# CY8C4xxx register map
File version: 0.1
Registers are 8-bit, read-write, no defined reset value unless marked. A register's access mark holds for its fields unless they carry their own. Offsets are from the block's base; [hi:lo] are bit positions; {n}, {i} and the like mark numbered series; 'fields as' and 'values as' point back to an identical list.

## UDB_P0_U0 — Single UDB Configuration
Base 0x400F3000; alternate view of UDB
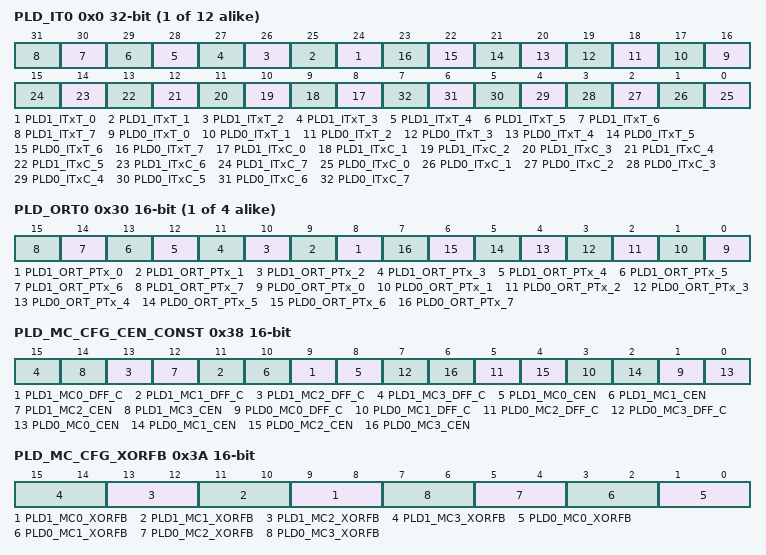
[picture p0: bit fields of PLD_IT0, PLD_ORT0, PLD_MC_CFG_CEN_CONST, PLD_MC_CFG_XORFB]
{0x0+4i} PLD_IT{i} 32-bit (i=0..11) — PLD Input Terms
  [n+24] PLD1_ITxT_{n} (n=0..7) — True input term. Bit position corresponds to product term.
  [n+16] PLD0_ITxT_{n} (n=0..7) — True input term. Bit position corresponds to product term.
  [n+8] PLD1_ITxC_{n} (n=0..7) — Complement input term. Bit position corresponds to product term
  [n] PLD0_ITxC_{n} (n=0..7) — Complement input term. Bit position corresponds to product term
{0x30+2i} PLD_ORT{i} 16-bit (i=0..3) — PLD OR Terms
  [n+8] PLD1_ORT_PTx_{n} (n=0..7) — OR term. Bit position corresponds to product term.
  [n] PLD0_ORT_PTx_{n} (n=0..7) — OR term. Bit position corresponds to product term.
0x38 PLD_MC_CFG_CEN_CONST 16-bit — Macrocell configuration for Carry Enable and Constant
  [2n+9] PLD1_MC{n}_DFF_C (n=0..3) — DFF Constant
    0=NOINV; 1=INVERTED
  [2n+8] PLD1_MC{n}_CEN (n=0..3) — Carry enable
    0=DISABLE; 1=ENABLE
  [2n+1] PLD0_MC{n}_DFF_C (n=0..3) — DFF Constant
    0=NOINV; 1=INVERTED
  [2n] PLD0_MC{n}_CEN (n=0..3) — Carry enable
    0=DISABLE; 1=ENABLE
0x3A PLD_MC_CFG_XORFB 16-bit — PLD Macro cell XOR feedback
  [all] fields
    0=DFF; 1=CARRY; 2=TFF_H; 3=TFF_L
  [2n+9:2n+8] PLD1_MC{n}_XORFB (n=0..3) — XOR feedback
  [2n+1:2n] PLD0_MC{n}_XORFB (n=0..3) — XOR feedback
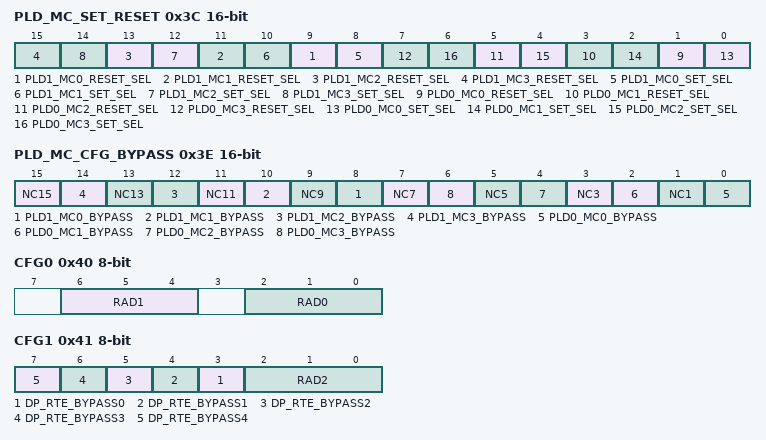
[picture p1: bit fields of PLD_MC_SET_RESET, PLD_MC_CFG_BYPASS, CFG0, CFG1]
0x3C PLD_MC_SET_RESET 16-bit — PLD Macro cell Set Reset Selection
  [all] fields
    0=DISABLE; 1=ENABLE
  [2n+9] PLD1_MC{n}_RESET_SEL (n=0..3) — Reset select enable
  [2n+8] PLD1_MC{n}_SET_SEL (n=0..3) — Set select enable
  [2n+1] PLD0_MC{n}_RESET_SEL (n=0..3) — Reset select enable
  [2n] PLD0_MC{n}_SET_SEL (n=0..3) — Set select enable
0x3E PLD_MC_CFG_BYPASS 16-bit — PLD Macro cell Bypass control
  [15] NC15 — Spare register bit
  [2n+8] PLD1_MC{n}_BYPASS (n=0..3) — Bypass selection
    0=REGISTER; 1=COMBINATIONAL
  [13] NC13 — Spare register bit
  [11] NC11 — Spare register bit
  [9] NC9 — Spare register bit
  [7] NC7 — Spare register bit
  [2n] PLD0_MC{n}_BYPASS (n=0..3) — Bypass selection
    0=REGISTER; 1=COMBINATIONAL
  [5] NC5 — Spare register bit
  [3] NC3 — Spare register bit
  [1] NC1 — Spare register bit
0x40 CFG0 — Datapath Input Selection - RAD1 RAD0. Address bits 0 and 1 to the dynamic configuration RAM
  [6:4] RAD1 — Datapath Permutable Input Mux
    0=OFF; {v}=DP_IN{v-1} (v=1..6)
  [2:0] RAD0 — Datapath Permutable Input Mux
    0=OFF; {v}=DP_IN{v-1} (v=1..6)
0x41 CFG1 — Datapath Input Selection - RAD2. Address bit 2 to the dynamic configuration RAM
  [n+3] DP_RTE_BYPASS{n} (n=0..4) — DP_In bypass ctl
    0=DP_IN{n}_ROUTE; 1=DP_IN{n}_BYPASS
  [2:0] RAD2 — Datapath Permutable Input Mux
    0=OFF; {v}=DP_IN{v-1} (v=1..6)
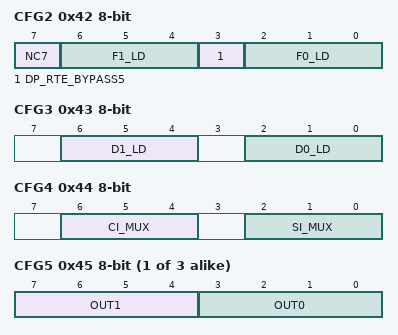
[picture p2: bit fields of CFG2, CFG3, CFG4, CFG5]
0x42 CFG2 — Datapath Input Selection - F1_LD, F0_LD.
  [7] NC7 — Spare register bit
  [6:4] F1_LD — Datapath Permutable Input Mux
    0=OFF; {v}=DP_IN{v-1} (v=1..6)
  [3] DP_RTE_BYPASS5 — DP_In bypass ctl
    0=DP_IN5_ROUTE; 1=DP_IN5_BYPASS
  [2:0] F0_LD — Datapath Permutable Input Mux
    0=OFF; {v}=DP_IN{v-1} (v=1..6)
0x43 CFG3 — Datapath Input Selection - D1_LD, D0_LD.
  [6:4] D1_LD — Datapath Permutable Input Mux
    0=OFF; {v}=DP_IN{v-1} (v=1..6)
  [2:0] D0_LD — Datapath Permutable Input Mux
    0=OFF; {v}=DP_IN{v-1} (v=1..6)
0x44 CFG4 — Datapath Input Selection - CI_MUX SI_MUX.
  [6:4] CI_MUX — Datapath Permutable Input Mux
    0=OFF; {v}=DP_IN{v-1} (v=1..6)
  [2:0] SI_MUX — Datapath Permutable Input Mux
    0=OFF; {v}=DP_IN{v-1} (v=1..6)
{0x40+i} CFG{i} (i=5..7) — Datapath Output Selection for OUT{2i-9} OUT{2i-10}
  [7:4] OUT{2i-9} — Datapath Permutable Output Mux
    0=CE0; 1=CL0; 2=Z0; 3=FF0; 4=CE1; 5=CL1; 6=Z1; 7=FF1; 8=OV_MSB; 9=CO_MSB; 10=CMSBO; 11=SO; 12=F0_BLK_STAT; 13=F1_BLK_STAT; 14=F0_BUS_STAT; 15=F1_BUS_STAT
  [3:0] OUT{2i-10} — Datapath Permutable Output Mux
    values as OUT{2i-9}
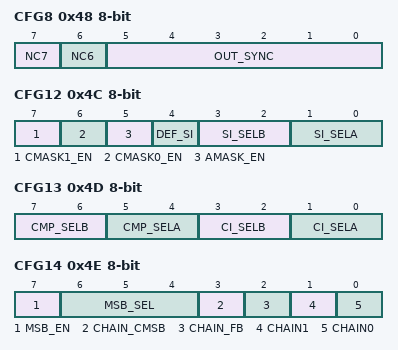
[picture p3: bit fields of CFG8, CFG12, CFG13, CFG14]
0x48 CFG8 — Datapath Output Synchronization Option
  [7] NC7 — Spare register bit
  [6] NC6 — Spare register bit
  [5:0] OUT_SYNC — Datapath Output Synchronization. Each datapath output can be registered (default,0), or combinational (1)
    0=REGISTERED; 1=COMBINATIONAL
0x49 CFG9 — Datapath ALU Mask
  [7:0] AMASK — Datapath ALU Mask. The mask value in this register is applied to the output of the Datapath ALU result before the result is stored. The AMASK_EN bit (CFG12) must be set for the mask to be operational.
0x4A CFG10 — Datapath Compare 0 Mask
  [7:0] CMASK0 — Datapath Compare 0 Mask. The mask value in this register is applied to the output of the Accumulator 0 before it is used for comparison in Compare block 0. The CMASK0_EN bit (CFG12) must be set for the mask to be operational.
0x4B CFG11 — Datapath Compare 1 Mask
  [7:0] CMASK0 — Datapath Compare 1 Mask. The mask value in this register is applied to the selected Compare 1 block input (Accumulator 0 or Accumulator 1) before it is used for comparison. The CMASK1_EN bit (CFG12) must be set for the mask to be operational.
0x4C CFG12 — Datapath mask enables and shift in configuration
  [7] CMASK1_EN — Datapath mask enable
    0=DISABLE; 1=ENABLE
  [6] CMASK0_EN — Datapath mask enable
    0=DISABLE; 1=ENABLE
  [5] AMASK_EN — Datapath mask enable
    0=DISABLE; 1=ENABLE
  [4] DEF_SI — Datapath default shift value
    0=DEFAULT_0; 1=DEFAULT_1
  [3:2] SI_SELB — Datapath shift in source select
    0=DEFAULT; 1=REGISTERED; 2=ROUTE; 3=CHAIN
  [1:0] SI_SELA — Datapath shift in source select
    0=DEFAULT; 1=REGISTERED; 2=ROUTE; 3=CHAIN
0x4D CFG13 — Datapath carry in and compare configuration
  [7:6] CMP_SELB — Datapath compare select
    0=A1_D1; 1=A1_A0; 2=A0_D1; 3=A0_A0
  [5:4] CMP_SELA — Datapath compare select
    0=A1_D1; 1=A1_A0; 2=A0_D1; 3=A0_A0
  [3:2] CI_SELB — Datapath carry in source select
    0=DEFAULT; 1=REGISTERED; 2=ROUTE; 3=CHAIN
  [1:0] CI_SELA — Datapath carry in source select
    0=DEFAULT; 1=REGISTERED; 2=ROUTE; 3=CHAIN
0x4E CFG14 — Datapath chaining and MSB configuration
  [7] MSB_EN — Datapath MSB selection enable
    0=DISABLE; 1=ENABLE
  [6:4] MSB_SEL — Datapath MSB Selection
    {v}=BIT{v} (v=0..7)
  [3] CHAIN_CMSB — Datapath CRC MSB chaining enable
    0=DISABLE; 1=ENABLE
  [2] CHAIN_FB — Datapath CRC feedback chaining enable
    0=DISABLE; 1=ENABLE
  [1] CHAIN1 — Datapath condition chaining enable
    0=DISABLE; 1=ENABLE
  [0] CHAIN0 — Datapath condition chaining enable
    0=DISABLE; 1=ENABLE
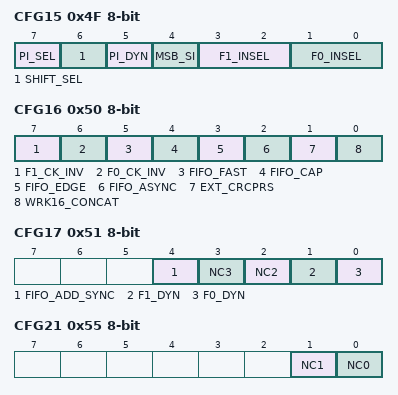
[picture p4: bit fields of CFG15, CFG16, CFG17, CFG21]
0x4F CFG15 — Datapath FIFO, shift and parallel input control
  [7] PI_SEL — Datapath parallel input selection
    0=NORMAL; 1=PARALLEL
  [6] SHIFT_SEL — Datapath shift out selection
    0=SOL_MSB; 1=SOR
  [5] PI_DYN — Enable for dynamic control of parallel data input (PI) mux.
    0=DISABLE; 1=ENABLE
  [4] MSB_SI — Arithmetic shift right operation shift in selection
    0=DEFAULT; 1=MSB
  [3:2] F1_INSEL — Datapath FIFO Configuration
    0=INPUT; 1=OUTPUT_A0; 2=OUTPUT_A1; 3=OUTPUT_ALU
  [1:0] F0_INSEL — Datapath FIFO Configuration
    0=INPUT; 1=OUTPUT_A0; 2=OUTPUT_A1; 3=OUTPUT_ALU
0x50 CFG16 — Datapath FIFO and register access configuration control
  [7] F1_CK_INV — FIFO Clock Invert. When this bit is set, the polarity of the clock for the given FIFO will be inverted, with respect to the polarity of the selected Datapath clock.
    0=NORMAL; 1=INVERT
  [6] F0_CK_INV — FIFO Clock Invert. When this bit is set, the polarity of the clock for the given FIFO will be inverted, with respect to the polarity of the selected Datapath clock.
    0=NORMAL; 1=INVERT
  [5] FIFO_FAST — FIFO Fast Mode. When this bit is set, the FIFO write logic is clocked by the application bus clock. Lowers the latency of capture timing, at the expense of additional power.
    0=DISABLE; 1=ENABLE
  [4] FIFO_CAP — FIFO Software Capture Mode. When this bit is set, a read of A0 or A1 triggers a capture into F0 or F1 respectively. This function follows the chaining configuration. All accumulators in the chain from a given block to the MS block in the chain are capture
    0=DISABLE; 1=ENABLE
  [3] FIFO_EDGE — Edge/level sensitive FIFO write control (Fx_LD). Only applies to FIFO configured in output mode
    0=LEVEL; 1=EDGE
  [2] FIFO_ASYNC — Asynchronous FIFO clocking support
    0=DISABLE; 1=ENABLE
  [1] EXT_CRCPRS — External CRC/PRS mode
    0=INTERNAL; 1=EXTERNAL
  [0] WRK16_CONCAT — Datapath register access mode
    0=DEFAULT; 1=CONCATENATE
0x51 CFG17 — Datapath FIFO control
  [4] FIFO_ADD_SYNC — Adds an additional sync flip-flop to FIFO block status.
    0=DISABLE; 1=ENABLE
  [3] NC3 — Spare register bit
  [2] NC2 — Spare register bit
  [1] F1_DYN
    0=STATIC; 1=DYNAMIC
  [0] F0_DYN — When this bit is set, the associated FIFO configuration may be dynamically controlled.
    0=STATIC; 1=DYNAMIC
0x52 CFG18 — Control Register Mode 0 (used in conjunction with Control Register Mode 1)
  [7:0] CTL_MD0 — CTL_MD1 and CTL_MD0 are concatenated to form an encoding for the mode of each control bit in the control register.
    0=DIRECT; 1=SYNC; 2=DOUBLE_SYNC; 3=PULSE
0x53 CFG19 — Control Register Mode 1 (used in conjunction with Control Register Mode 0)
  [7:0] CTL_MD1 — CTL_MD1 and CTL_MD0 are concatenated to form an encoding for the mode of each control bit in the control register.
    0=DIRECT; 1=SYNC; 2=DOUBLE_SYNC; 3=PULSE
0x54 CFG20 — Status Register input mode selection
  [7:0] STAT_MD — Mode selection for each bit of the status register. A '0' is transparent mode, where internal routing is read idrectly by CPU firmware. A '1' is sticky-clear-on-read mode, where once the given bit is set, it will stay set until the CPU reads the bit.
0x55 CFG21 — Spare register bits
  [1] NC1 — Spare register bit
  [0] NC0 — Spare register bit
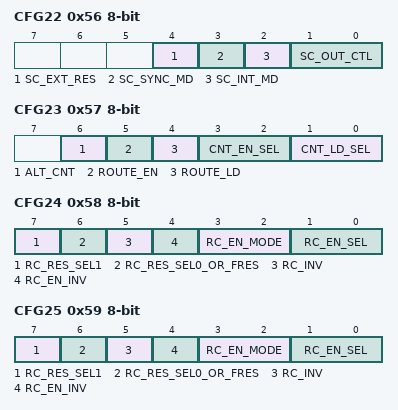
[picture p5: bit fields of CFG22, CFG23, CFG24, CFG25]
0x56 CFG22 — SC block configuration control
  [4] SC_EXT_RES — Control register external reset operation. This bit supports autonomous usage of the control register, where a routed reset should clear the writable input registers. By default this is off because the CPU writable register can be cleared in firmware. In
    0=DISABLED; 1=ENABLED
  [3] SC_SYNC_MD — SC Sync Mode - controls when the status register operates as a 4-bit double synchronizer module
    0=NORMAL; 1=SYNC_MODE
  [2] SC_INT_MD — SC Interrupt Mode - controls when the UDB driving an interrupt generated from the masked OR reduction of status bits 6 to 0
    0=NORMAL; 1=INT_MODE
  [1:0] SC_OUT_CTL — Selects the output source for the Status and Control routing connections
    0=CONTROL; 1=PARALLEL; 2=COUNTER
0x57 CFG23 — Counter Control
  [6] ALT_CNT — Configure the alternate operating mode of the counter
    0=DEFAULT_MODE; 1=ALT_MODE
  [5] ROUTE_EN — Configure the counter enable signal for routing input
    0=DISABLE; 1=ROUTED
  [4] ROUTE_LD — Configure the counter load signal for routing input
    0=DISABLE; 1=ROUTED
  [3:2] CNT_EN_SEL — Selects the routing inputs for the counter enable signal
    0=SC_IN4; 1=SC_IN5; 2=SC_IN6; 3=SC_IO
  [1:0] CNT_LD_SEL — Selects the routing inputs for the counter load signal
    {v}=SC_IN{v} (v=0..3)
0x58 CFG24 — PLD0 Clock and Reset control
  [7] RC_RES_SEL1 — Configures the routed reset for the associated UDB component block. The meaning of this bit depends on the value of ALT RES (CFG31). ?When ALT RES = '0' - This bit is not used. ?When ALT RES = '1' - The bits {RC_SEL1,RC_SEL0_OR_FRES} select the RC routing
  [6] RC_RES_SEL0_OR_FRES — Configures the routed or firmware reset for the associated UDB component block. The meaning of this bit depends on the value of ALT RES (CFG31). ?When ALT RES = '0' - This bit is a firmware reset. ?When ALT RES = '1' - The bits {RC_SEL1,RC_SEL0_OR_FRES} s
  [5] RC_INV — Optionally inverts the clock selection for the associated UDB component block.
    0=NOINV; 1=INVERT
  [4] RC_EN_INV — Optionally inverts the clock enable selection for the associated UDB component blocks.
    0=NOINV; 1=INVERT
  [3:2] RC_EN_MODE — Selects the operating mode for the clock to the associated UDB component block.
    0=OFF; 1=ON; 2=POSEDGE; 3=LEVEL
  [1:0] RC_EN_SEL — Selects channel route for enable control to the associated UDB component block
    {v}=RC_IN{v} (v=0..3)
0x59 CFG25 — PLD1 Clock and Reset control
  fields as CFG24
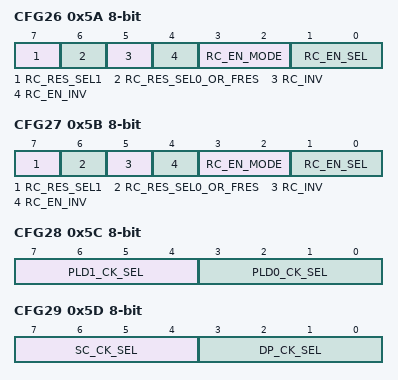
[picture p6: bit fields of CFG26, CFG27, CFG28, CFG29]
0x5A CFG26 — Datapath Clock and Reset control
  fields as CFG24
0x5B CFG27 — Status/Control Clock and Reset control
  fields as CFG24
0x5C CFG28 — Clock Selection for PLD1 and PLD0
  [7:4] PLD1_CK_SEL — Clock selection registers
    {v}=GCLK{v} (v=0..7); 8=EXT_CLK; 9=SYSCLK
  [3:0] PLD0_CK_SEL — Clock selection registers
    {v}=GCLK{v} (v=0..7); 8=EXT_CLK; 9=SYSCLK
0x5D CFG29 — Clock Selection for Datapath, Status and Control
  [7:4] SC_CK_SEL — Clock selection registers
    {v}=GCLK{v} (v=0..7); 8=EXT_CLK; 9=SYSCLK
  [3:0] DP_CK_SEL — Clock selection registers
    {v}=GCLK{v} (v=0..7); 8=EXT_CLK; 9=SYSCLK
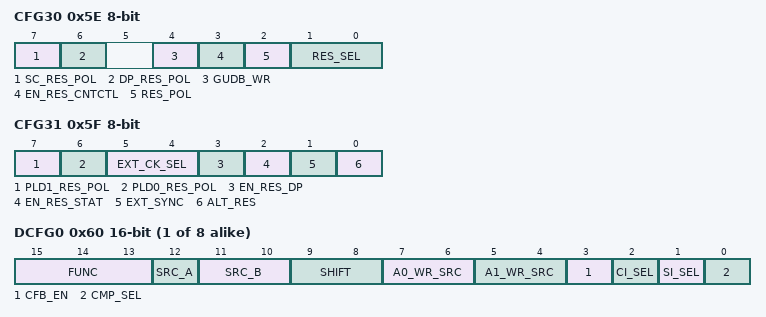
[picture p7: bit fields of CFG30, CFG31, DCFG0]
0x5E CFG30 — Reset control
  [7] SC_RES_POL — Only valid when ALT RES (CFG31) is '1'. This bit controls the polarity of the selected SC routed reset.
    0=NOINV; 1=INVERT
  [6] DP_RES_POL — Only valid when ALT RES (CFG31) is '1'. This bit controls the polarity of the selected Datapath routed reset.
    0=NOINV; 1=INVERT
  [4] GUDB_WR — Enable global write operation for the configuration and working registers in this UDB. When this bit is set, the UDB ID select decoding is bypassed.
    0=DISABLE; 1=ENABLE
  [3] EN_RES_CNTCTL — This bit gates the routed reset to the counter/control register. By default, the operation is compatible, i.e., it only applies to the counter. However, if the updated control regisiter modes are used (sync mode, pulse mode, or the ext res bit) then the r
    0=DISABLE; 1=ENABLE
  [2] RES_POL — The meaning of this bit depends on the value of the ALT RES bit in CFG31. When ALT RES is '0' (compatible mode), this bit sets the polarity of the routed reset. When ALT RES is '1', this bit is unused.
    0=NEGATED; 1=ASSERTED
  [1:0] RES_SEL — The meaning of this bit depends on the value of ALT RES (CFG31). When ALT RES is '0' (compatible mode), this 2 bit field selects the RC routing input for the compatible reset scheme. When the ALT RES bit is '1', these bits are not used.
    {v}=RC_IN{v} (v=0..3)
0x5F CFG31 — Reset control
  [7] PLD1_RES_POL — Not connected. NOTE: There is only one routed reset available to both PLDs in the UDB. When ALT RES is '1', PLD0 RES SEL controls the polarity of the routed reset for both PLDs.
    0=NOINV; 1=INVERT
  [6] PLD0_RES_POL — The meaning of this bit depends on the value of ALT RES. When ALT RES (CFG31) is '1', this bit controls the polarity of the selected PLD0 routed reset. NOTE: There is only one routed reset available in the PLD block for both PLDs, therefore this bit contr
    0=NOINV; 1=INVERT
  [5:4] EXT_CK_SEL — External clock selection
    {v}=RC_IN{v} (v=0..3)
  [3] EN_RES_DP — Only valid when ALT RES (CFG31) is '1'. This bit gates the routed reset to the Datapath block.
    0=DISABLE; 1=ENABLE
  [2] EN_RES_STAT — Only valid when ALT RES (CFG31) is '1'. This bit gates the routed reset to the status register.
    0=NEGATED; 1=ASSERTED
  [1] EXT_SYNC — Enable synchronization of selected external clock
    0=DISABLE; 1=ENABLE
  [0] ALT_RES — This bit toggles between two reset configurations. When this bit is '0', one routed reset is shared by all components in this UDB (compatible mode). When this bit is a 1, each block can select a unique routed reset from the available RC inputs.;
    0=COMPATIBLE; 1=ALTERNATE
{0x60+2i} DCFG{i} 16-bit (i=0..7) — Dynamic Configuration RAM
  [15:13] FUNC — Dynamic ALU function selection
    0=PASS; 1=INC_A; 2=DEC_A; 3=ADD; 4=SUB; 5=XOR; 6=AND; 7=OR
  [12] SRC_A — Dynamic ALU source A selection
    0=A0; 1=A1
  [11:10] SRC_B — Dynamic ALU source B selection
    0=D0; 1=D1; 2=A0; 3=A1
  [9:8] SHIFT — Dynamic shift selection
    0=NOSHIFT; 1=LEFT; 2=RIGHT; 3=SWAP
  [7:6] A0_WR_SRC — Dynamic A0 write source selection
    0=NOWRITE; 1=ALU; 2=D0; 3=F0
  [5:4] A1_WR_SRC — Dynamic A1 write source selection
    0=NOWRITE; 1=ALU; 2=D1; 3=F1
  [3] CFB_EN — Dynamic CRC feedback selection
    0=DISABLE; 1=ENABLE
  [2] CI_SEL — Dynamic carry in selection
    0=CFG_A; 1=CFG_B
  [1] SI_SEL — Dynamic shift in selection
    0=CFG_A; 1=CFG_B
  [0] CMP_SEL — Dynamic compare selection
    0=CFG_A; 1=CFG_B

## UDB_P0_U1 — Single UDB Configuration
Base 0x400F3080; alternate view of UDB
Registers as UDB_P0_U0.

## UDB_P1_U0 — Single UDB Configuration
Base 0x400F3200; alternate view of UDB
Registers as UDB_P0_U0.

## UDB_P1_U1 — Single UDB Configuration
Base 0x400F3280; alternate view of UDB
Registers as UDB_P0_U0.
